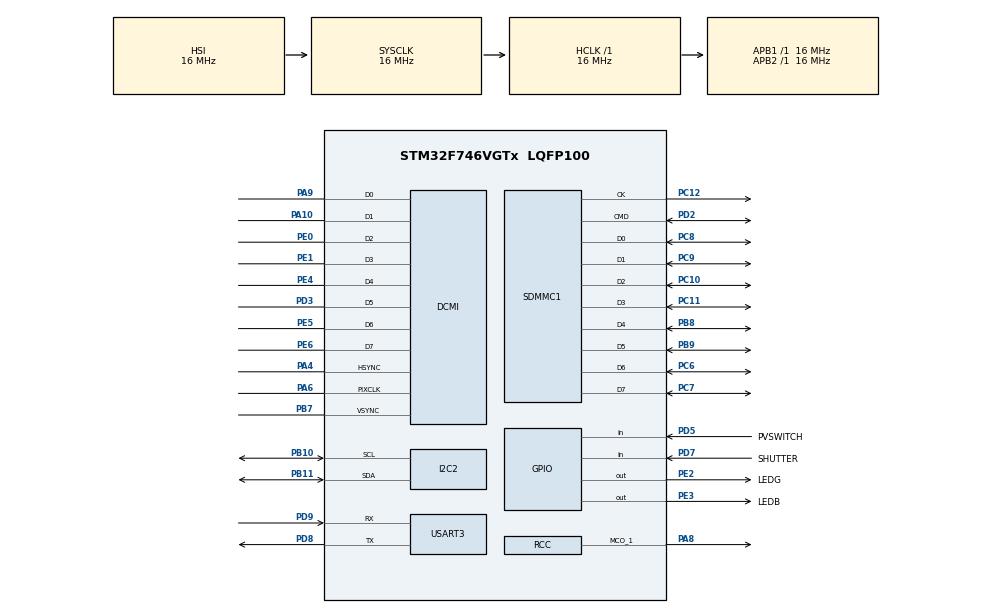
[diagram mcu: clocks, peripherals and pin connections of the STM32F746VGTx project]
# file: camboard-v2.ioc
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Mcu.Family=STM32F7
Mcu.Name=STM32F746VGTx
Mcu.Package=LQFP100
NVIC.PriorityGroup=NVIC_PRIORITYGROUP_4
PA10.Mode=Slave_8_bits_External_Synchro
PA10.Signal=DCMI_D1
PA13.Mode=JTAG_5_pins
PA13.Signal=SYS_JTMS-SWDIO
PA14.Mode=JTAG_5_pins
PA14.Signal=SYS_JTCK-SWCLK
PA15.Mode=JTAG_5_pins
PA15.Signal=SYS_JTDI
PA4.Mode=Slave_8_bits_External_Synchro
PA4.Signal=DCMI_HSYNC
PA6.Mode=Slave_8_bits_External_Synchro
PA6.Signal=DCMI_PIXCLK
PA8.Mode=Clock-out-1
PA8.Signal=RCC_MCO_1
PA9.Mode=Slave_8_bits_External_Synchro
PA9.Signal=DCMI_D0
PB10.Mode=I2C
PB10.Signal=I2C2_SCL
PB11.Mode=I2C
PB11.Signal=I2C2_SDA
PB3.Mode=JTAG_5_pins
PB3.Signal=SYS_JTDO-SWO
PB4.Mode=JTAG_5_pins
PB4.Signal=SYS_JTRST
PB7.Mode=Slave_8_bits_External_Synchro
PB7.Signal=DCMI_VSYNC
PB8.Mode=mmc_8_bits_Wide_bus
PB8.Signal=SDMMC1_D4
PB9.Mode=mmc_8_bits_Wide_bus
PB9.Signal=SDMMC1_D5
PC10.Mode=mmc_8_bits_Wide_bus
PC10.Signal=SDMMC1_D2
PC11.Mode=mmc_8_bits_Wide_bus
PC11.Signal=SDMMC1_D3
PC12.Mode=mmc_8_bits_Wide_bus
PC12.Signal=SDMMC1_CK
PC14/OSC32_IN.Mode=LSE-External-Oscillator
PC14/OSC32_IN.Signal=RCC_OSC32_IN
PC15/OSC32_OUT.Mode=LSE-External-Oscillator
PC15/OSC32_OUT.Signal=RCC_OSC32_OUT
PC6.Mode=mmc_8_bits_Wide_bus
PC6.Signal=SDMMC1_D6
PC7.Mode=mmc_8_bits_Wide_bus
PC7.Signal=SDMMC1_D7
PC8.Mode=mmc_8_bits_Wide_bus
PC8.Signal=SDMMC1_D0
PC9.Mode=mmc_8_bits_Wide_bus
PC9.Signal=SDMMC1_D1
PD11.Signal=USART3_CTS
PD12.Signal=USART3_RTS
PD2.Mode=mmc_8_bits_Wide_bus
PD2.Signal=SDMMC1_CMD
PD3.Mode=Slave_8_bits_External_Synchro
PD3.Signal=DCMI_D5
PD5.GPIO_Label=PVSWITCH
PD5.Signal=GPIO_Input
PD7.GPIO_Label=SHUTTER
PD7.Signal=GPIO_Input
PD8.Mode=Asynchronous
PD8.Signal=USART3_TX
PD9.Mode=Asynchronous
PD9.Signal=USART3_RX
PE0.Mode=Slave_8_bits_External_Synchro
PE0.Signal=DCMI_D2
PE1.Mode=Slave_8_bits_External_Synchro
PE1.Signal=DCMI_D3
PE2.GPIO_Label=LEDG
PE2.Signal=GPIO_Output
PE3.GPIO_Label=LEDB
PE3.Signal=GPIO_Output
PE4.Mode=Slave_8_bits_External_Synchro
PE4.Signal=DCMI_D4
PE5.Mode=Slave_8_bits_External_Synchro
PE5.Signal=DCMI_D6
PE6.Mode=Slave_8_bits_External_Synchro
PE6.Signal=DCMI_D7
PH0/OSC_IN.Mode=HSE-External-Oscillator
PH0/OSC_IN.Signal=RCC_OSC_IN
PH1/OSC_OUT.Mode=HSE-External-Oscillator
PH1/OSC_OUT.Signal=RCC_OSC_OUT
ProjectManager.HeapSize=0x200
ProjectManager.StackSize=0x400
ProjectManager.TargetToolchain=SW4STM32
RCC.AHBFreq_Value=16000000
RCC.APB1Freq_Value=16000000
RCC.APB1TimFreq_Value=16000000
RCC.APB2Freq_Value=16000000
RCC.APB2TimFreq_Value=16000000
RCC.CortexFreq_Value=16000000
RCC.HCLKFreq_Value=16000000
RCC.HSE_VALUE=25000000
RCC.HSI_VALUE=16000000
RCC.SYSCLKFreq_VALUE=16000000
RCC.USBFreq_Value=96000000
RCC.VCOOutputFreq_Value=192000000
USART3.VirtualMode-Asynchronous=VM_ASYNC
VP_RTC_VS_RTC_Activate.Mode=RTC_Enabled
board=camboard-v2

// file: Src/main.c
/**
  ******************************************************************************
  * File Name          : main.c
  * Description        : Main program body
  ******************************************************************************
  ** This notice applies to any and all portions of this file
  * that are not between comment pairs USER CODE BEGIN and
  * USER CODE END. Other portions of this file, whether
  * inserted by the user or by software development tools
  * are owned by their respective copyright owners.
  *
  * COPYRIGHT(c) 2017 STMicroelectronics
  *
  * Redistribution and use in source and binary forms, with or without modification,
  * are permitted provided that the following conditions are met:
  *   1. Redistributions of source code must retain the above copyright notice,
  *      this list of conditions and the following disclaimer.
  *   2. Redistributions in binary form must reproduce the above copyright notice,
  *      this list of conditions and the following disclaimer in the documentation
  *      and/or other materials provided with the distribution.
  *   3. Neither the name of STMicroelectronics nor the names of its contributors
  *      may be used to endorse or promote products derived from this software
  *      without specific prior written permission.
  *
  * THIS SOFTWARE IS PROVIDED BY THE COPYRIGHT HOLDERS AND CONTRIBUTORS "AS IS"
  * AND ANY EXPRESS OR IMPLIED WARRANTIES, INCLUDING, BUT NOT LIMITED TO, THE
  * IMPLIED WARRANTIES OF MERCHANTABILITY AND FITNESS FOR A PARTICULAR PURPOSE ARE
  * DISCLAIMED. IN NO EVENT SHALL THE COPYRIGHT HOLDER OR CONTRIBUTORS BE LIABLE
  * FOR ANY DIRECT, INDIRECT, INCIDENTAL, SPECIAL, EXEMPLARY, OR CONSEQUENTIAL
  * DAMAGES (INCLUDING, BUT NOT LIMITED TO, PROCUREMENT OF SUBSTITUTE GOODS OR
  * SERVICES; LOSS OF USE, DATA, OR PROFITS; OR BUSINESS INTERRUPTION) HOWEVER
  * CAUSED AND ON ANY THEORY OF LIABILITY, WHETHER IN CONTRACT, STRICT LIABILITY,
  * OR TORT (INCLUDING NEGLIGENCE OR OTHERWISE) ARISING IN ANY WAY OUT OF THE USE
  * OF THIS SOFTWARE, EVEN IF ADVISED OF THE POSSIBILITY OF SUCH DAMAGE.
  *
  ******************************************************************************
  */

#include "main.h"
#include "stm32f7xx_hal.h"

DCMI_HandleTypeDef hdcmi;

I2C_HandleTypeDef hi2c2;

RTC_HandleTypeDef hrtc;

MMC_HandleTypeDef hmmc1;

UART_HandleTypeDef huart3;

/* USER CODE BEGIN PV */
/* Private variables ---------------------------------------------------------*/

/* USER CODE END PV */

void SystemClock_Config(void);
static void MX_GPIO_Init(void);
static void MX_RTC_Init(void);
static void MX_I2C2_Init(void);
static void MX_USART3_UART_Init(void);
static void MX_SDMMC1_MMC_Init(void);
static void MX_DCMI_Init(void);

/* USER CODE BEGIN PFP */
/* Private function prototypes -----------------------------------------------*/

/* USER CODE END PFP */

int main(void)
{

  /* MCU Configuration----------------------------------------------------------*/

  /* Reset of all peripherals, Initializes the Flash interface and the Systick. */
  HAL_Init();

  /* Configure the system clock */
  SystemClock_Config();

  /* Initialize all configured peripherals */
  MX_GPIO_Init();
  MX_RTC_Init();
  MX_I2C2_Init();
  MX_USART3_UART_Init();
  MX_SDMMC1_MMC_Init();
  MX_DCMI_Init();

  /* Infinite loop */
  /* USER CODE BEGIN WHILE */
  while (1)
  {
	  HAL_GPIO_TogglePin(LEDB_GPIO_Port, LEDB_Pin);
	  HAL_Delay(500);
  /* USER CODE END WHILE */

  }

}

/** System Clock Configuration
*/
void SystemClock_Config(void)
{

  RCC_OscInitTypeDef RCC_OscInitStruct;
  RCC_ClkInitTypeDef RCC_ClkInitStruct;
  RCC_PeriphCLKInitTypeDef PeriphClkInitStruct;

    /**Configure the main internal regulator output voltage
    */
  __HAL_RCC_PWR_CLK_ENABLE();

  __HAL_PWR_VOLTAGESCALING_CONFIG(PWR_REGULATOR_VOLTAGE_SCALE3);

    /**Initializes the CPU, AHB and APB busses clocks
    */
  RCC_OscInitStruct.OscillatorType = RCC_OSCILLATORTYPE_HSI|RCC_OSCILLATORTYPE_LSI;
  RCC_OscInitStruct.HSIState = RCC_HSI_ON;
  RCC_OscInitStruct.HSICalibrationValue = 16;
  RCC_OscInitStruct.LSIState = RCC_LSI_ON;
  RCC_OscInitStruct.PLL.PLLState = RCC_PLL_NONE;
  if (HAL_RCC_OscConfig(&RCC_OscInitStruct) != HAL_OK)
  {
    _Error_Handler(__FILE__, __LINE__);
  }

    /**Initializes the CPU, AHB and APB busses clocks
    */
  RCC_ClkInitStruct.ClockType = RCC_CLOCKTYPE_HCLK|RCC_CLOCKTYPE_SYSCLK
                              |RCC_CLOCKTYPE_PCLK1|RCC_CLOCKTYPE_PCLK2;
  RCC_ClkInitStruct.SYSCLKSource = RCC_SYSCLKSOURCE_HSI;
  RCC_ClkInitStruct.AHBCLKDivider = RCC_SYSCLK_DIV1;
  RCC_ClkInitStruct.APB1CLKDivider = RCC_HCLK_DIV1;
  RCC_ClkInitStruct.APB2CLKDivider = RCC_HCLK_DIV1;

  if (HAL_RCC_ClockConfig(&RCC_ClkInitStruct, FLASH_LATENCY_0) != HAL_OK)
  {
    _Error_Handler(__FILE__, __LINE__);
  }

  PeriphClkInitStruct.PeriphClockSelection = RCC_PERIPHCLK_RTC|RCC_PERIPHCLK_USART3
                              |RCC_PERIPHCLK_I2C2|RCC_PERIPHCLK_SDMMC1;
  PeriphClkInitStruct.RTCClockSelection = RCC_RTCCLKSOURCE_LSI;
  PeriphClkInitStruct.Usart3ClockSelection = RCC_USART3CLKSOURCE_PCLK1;
  PeriphClkInitStruct.I2c2ClockSelection = RCC_I2C2CLKSOURCE_PCLK1;
  PeriphClkInitStruct.Sdmmc1ClockSelection = RCC_SDMMC1CLKSOURCE_SYSCLK;
  if (HAL_RCCEx_PeriphCLKConfig(&PeriphClkInitStruct) != HAL_OK)
  {
    _Error_Handler(__FILE__, __LINE__);
  }

  HAL_RCC_MCOConfig(RCC_MCO1, RCC_MCO1SOURCE_HSI, RCC_MCODIV_1);

    /**Configure the Systick interrupt time
    */
  HAL_SYSTICK_Config(HAL_RCC_GetHCLKFreq()/1000);

    /**Configure the Systick
    */
  HAL_SYSTICK_CLKSourceConfig(SYSTICK_CLKSOURCE_HCLK);

  /* SysTick_IRQn interrupt configuration */
  HAL_NVIC_SetPriority(SysTick_IRQn, 0, 0);
}

/* DCMI init function */
static void MX_DCMI_Init(void)
{

  hdcmi.Instance = DCMI;
  hdcmi.Init.SynchroMode = DCMI_SYNCHRO_HARDWARE;
  hdcmi.Init.PCKPolarity = DCMI_PCKPOLARITY_FALLING;
  hdcmi.Init.VSPolarity = DCMI_VSPOLARITY_LOW;
  hdcmi.Init.HSPolarity = DCMI_HSPOLARITY_LOW;
  hdcmi.Init.CaptureRate = DCMI_CR_ALL_FRAME;
  hdcmi.Init.ExtendedDataMode = DCMI_EXTEND_DATA_8B;
  hdcmi.Init.JPEGMode = DCMI_JPEG_DISABLE;
  hdcmi.Init.ByteSelectMode = DCMI_BSM_ALL;
  hdcmi.Init.ByteSelectStart = DCMI_OEBS_ODD;
  hdcmi.Init.LineSelectMode = DCMI_LSM_ALL;
  hdcmi.Init.LineSelectStart = DCMI_OELS_ODD;
  if (HAL_DCMI_Init(&hdcmi) != HAL_OK)
  {
    _Error_Handler(__FILE__, __LINE__);
  }

}

/* I2C2 init function */
static void MX_I2C2_Init(void)
{

  hi2c2.Instance = I2C2;
  hi2c2.Init.Timing = 0x00303D5B;
  hi2c2.Init.OwnAddress1 = 0;
  hi2c2.Init.AddressingMode = I2C_ADDRESSINGMODE_7BIT;
  hi2c2.Init.DualAddressMode = I2C_DUALADDRESS_DISABLE;
  hi2c2.Init.OwnAddress2 = 0;
  hi2c2.Init.OwnAddress2Masks = I2C_OA2_NOMASK;
  hi2c2.Init.GeneralCallMode = I2C_GENERALCALL_DISABLE;
  hi2c2.Init.NoStretchMode = I2C_NOSTRETCH_DISABLE;
  if (HAL_I2C_Init(&hi2c2) != HAL_OK)
  {
    _Error_Handler(__FILE__, __LINE__);
  }

    /**Configure Analogue filter
    */
  if (HAL_I2CEx_ConfigAnalogFilter(&hi2c2, I2C_ANALOGFILTER_ENABLE) != HAL_OK)
  {
    _Error_Handler(__FILE__, __LINE__);
  }

    /**Configure Digital filter
    */
  if (HAL_I2CEx_ConfigDigitalFilter(&hi2c2, 0) != HAL_OK)
  {
    _Error_Handler(__FILE__, __LINE__);
  }

}

/* RTC init function */
static void MX_RTC_Init(void)
{

    /**Initialize RTC Only
    */
  hrtc.Instance = RTC;
  hrtc.Init.HourFormat = RTC_HOURFORMAT_24;
  hrtc.Init.AsynchPrediv = 127;
  hrtc.Init.SynchPrediv = 255;
  hrtc.Init.OutPut = RTC_OUTPUT_DISABLE;
  hrtc.Init.OutPutPolarity = RTC_OUTPUT_POLARITY_HIGH;
  hrtc.Init.OutPutType = RTC_OUTPUT_TYPE_OPENDRAIN;
  if (HAL_RTC_Init(&hrtc) != HAL_OK)
  {
    _Error_Handler(__FILE__, __LINE__);
  }

}

/* SDMMC1 init function */
static void MX_SDMMC1_MMC_Init(void)
{

  hmmc1.Instance = SDMMC1;
  hmmc1.Init.ClockEdge = SDMMC_CLOCK_EDGE_RISING;
  hmmc1.Init.ClockBypass = SDMMC_CLOCK_BYPASS_DISABLE;
  hmmc1.Init.ClockPowerSave = SDMMC_CLOCK_POWER_SAVE_DISABLE;
  hmmc1.Init.BusWide = SDMMC_BUS_WIDE_1B;
  hmmc1.Init.HardwareFlowControl = SDMMC_HARDWARE_FLOW_CONTROL_DISABLE;
  hmmc1.Init.ClockDiv = 0;
  if (HAL_MMC_Init(&hmmc1) != HAL_OK)
  {
    _Error_Handler(__FILE__, __LINE__);
  }

  if (HAL_MMC_ConfigWideBusOperation(&hmmc1, SDMMC_BUS_WIDE_8B) != HAL_OK)
  {
    _Error_Handler(__FILE__, __LINE__);
  }

}

/* USART3 init function */
static void MX_USART3_UART_Init(void)
{

  huart3.Instance = USART3;
  huart3.Init.BaudRate = 115200;
  huart3.Init.WordLength = UART_WORDLENGTH_7B;
  huart3.Init.StopBits = UART_STOPBITS_1;
  huart3.Init.Parity = UART_PARITY_NONE;
  huart3.Init.Mode = UART_MODE_TX_RX;
  huart3.Init.HwFlowCtl = UART_HWCONTROL_NONE;
  huart3.Init.OverSampling = UART_OVERSAMPLING_16;
  huart3.Init.OneBitSampling = UART_ONE_BIT_SAMPLE_DISABLE;
  huart3.AdvancedInit.AdvFeatureInit = UART_ADVFEATURE_NO_INIT;
  if (HAL_UART_Init(&huart3) != HAL_OK)
  {
    _Error_Handler(__FILE__, __LINE__);
  }

}

/** Configure pins as
        * Analog
        * Input
        * Output
        * EVENT_OUT
        * EXTI
     PA8   ------> RCC_MCO_1
*/
static void MX_GPIO_Init(void)
{

  GPIO_InitTypeDef GPIO_InitStruct;

  /* GPIO Ports Clock Enable */
  __HAL_RCC_GPIOE_CLK_ENABLE();
  __HAL_RCC_GPIOC_CLK_ENABLE();
  __HAL_RCC_GPIOH_CLK_ENABLE();
  __HAL_RCC_GPIOA_CLK_ENABLE();
  __HAL_RCC_GPIOB_CLK_ENABLE();
  __HAL_RCC_GPIOD_CLK_ENABLE();

  /*Configure GPIO pin Output Level */
  HAL_GPIO_WritePin(GPIOE, LEDG_Pin|LEDB_Pin, GPIO_PIN_RESET);

  /*Configure GPIO pins : LEDG_Pin LEDB_Pin */
  GPIO_InitStruct.Pin = LEDG_Pin|LEDB_Pin;
  GPIO_InitStruct.Mode = GPIO_MODE_OUTPUT_PP;
  GPIO_InitStruct.Pull = GPIO_NOPULL;
  GPIO_InitStruct.Speed = GPIO_SPEED_FREQ_LOW;
  HAL_GPIO_Init(GPIOE, &GPIO_InitStruct);

  /*Configure GPIO pin : PA8 */
  GPIO_InitStruct.Pin = GPIO_PIN_8;
  GPIO_InitStruct.Mode = GPIO_MODE_AF_PP;
  GPIO_InitStruct.Pull = GPIO_NOPULL;
  GPIO_InitStruct.Speed = GPIO_SPEED_FREQ_LOW;
  GPIO_InitStruct.Alternate = GPIO_AF0_MCO;
  HAL_GPIO_Init(GPIOA, &GPIO_InitStruct);

  /*Configure GPIO pins : PVSWITCH_Pin SHUTTER_Pin */
  GPIO_InitStruct.Pin = PVSWITCH_Pin|SHUTTER_Pin;
  GPIO_InitStruct.Mode = GPIO_MODE_INPUT;
  GPIO_InitStruct.Pull = GPIO_NOPULL;
  HAL_GPIO_Init(GPIOD, &GPIO_InitStruct);

}

void _Error_Handler(char * file, int line)
{
  while(1)
  {
  }
}

/************************ (C) COPYRIGHT STMicroelectronics *****END OF FILE****/
